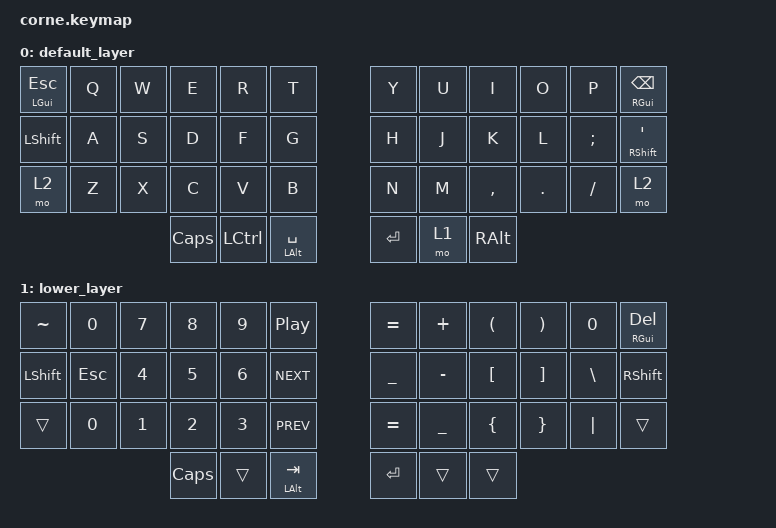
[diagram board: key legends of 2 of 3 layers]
/*
 * Copyright (c) 2020 The ZMK Contributors
 *
 * SPDX-License-Identifier: MIT
 */

#include <behaviors.dtsi>
#include <dt-bindings/zmk/keys.h>
#include <dt-bindings/zmk/bt.h>

/ {
        keymap {
                compatible = "zmk,keymap";
                default_layer {
// -----------------------------------------------------------------------------------------
// |  ESC |  Q  |  W  |  E  |  R  |  T  |   |  Y  |  U   |  I  |  O  |  P  | BSPC |
// | SHFT |  A  |  S  |  D  |  F  |  G  |   |  H  |  J   |  K  |  L  |  ;  |  '   |
// | LWR  |  Z  |  X  |  C  |  V  |  B  |   |  N  |  M   |  ,  |  .  |  /  | RSE  |
//                    | GUI | CTRL| SPC |   | RET | LWR  | RSE |
                        bindings = <
   &mt LGUI ESC   &kp Q       &kp W      &kp E      &kp R &kp T      &kp Y &kp U  &kp I      &kp O      &kp P     &mt RGUI BSPC
   &kp LSHFT      &kp A       &kp S      &kp D      &kp F &kp G      &kp H &kp J  &kp K      &kp L      &kp SEMI  &mt RSHFT SQT
   &mo 2          &kp Z       &kp X      &kp C      &kp V &kp B      &kp N &kp M  &kp COMMA  &kp DOT    &kp FSLH  &mo 2
                  &kp CAPS    &kp LCTRL  &mt LALT SPACE              &kp RET  &mo 1 &kp RALT
                        >;
                };
                lower_layer {
// -----------------------------------------------------------------------------------------
// |  ~   |  0  |  7  |  8  |  9  |  0  |   |  =  |  +  |  (  |  )  |  0  | DEL  |
// | SHFT |  0  |  4  |  5  |  6  |  0  |   |  _  |  -  |  [  |  ]  |  \  | SHFT |
// | LWR  |  0  |  1  |  2  |  3  |  0  |   |  =  |  _  |  {  |  }  | "|" | RSE  |
//                    | GUI | CTRL| TAB |   | RET |     |     |
                        bindings = <
   &kp TILDE &kp N0   &kp N7 &kp N8   &kp N9    &kp C_PP    &kp EQUAL &kp PLUS  &kp LPAR       &kp RPAR      &kp N0         &mt RGUI DEL
   &kp LSHFT &kp ESC  &kp N4 &kp N5   &kp N6    &kp C_NEXT  &kp UNDER &kp MINUS &kp LBKT       &kp RBKT      &kp BSLH       &kp RSHFT
   &trans    &kp N0   &kp N1 &kp N2   &kp N3    &kp C_PREV  &kp EQUAL &kp UNDER &kp LBRC       &kp RBRC      &kp PIPE       &trans
                             &kp CAPS &trans    &mt LALT TAB &kp RET   &trans    &trans
                        >;
                };
                raise_layer {
// -----------------------------------------------------------------------------------------
// |  `   |  !  |  &  |  *  |  (  | VOLU|   |  ^  |  &  |  *  |  (  |  )  | INS  |
// | SHFT | BT1 |  $  |  %  |  ^  | VOLD|   | LFT | DWN |  UP | RGT |  \  |  `   |
// | LWR  |BTCLR|  !  |  @  |  #  | VOLM|   | END | PGDN| PGUP| HOME| "|" | RSE  |
//                    | CAPS| CTRL| TAB |   | RET |     |     |
                        bindings = <
   &kp TILDE &kp EXCL     &kp AMPS     &kp ASTRK    &kp LPAR     &kp C_VOL_UP   &kp CARET &kp AMPS  &kp ASTRK &kp LPAR  &kp RPAR &kp INS
   &kp LSHFT &bt BT_SEL 0 &kp DLLR     &kp PRCNT    &kp CARET    &kp C_VOL_DN   &kp LEFT  &kp DOWN  &kp UP    &kp RIGHT &kp BSLH &kp GRAVE
   &trans    &bt BT_CLR   &kp EXCL     &kp AT       &kp HASH     &kp C_MUTE     &kp END   &kp PG_DN &kp PG_UP &kp HOME  &kp PIPE
                                       &kp CAPS     &trans       &kp TAB        &kp RET   &trans    &trans
                        >;
                };
        };
};
